# GD32F4xx register map
File version: 1.0
CPU: CM4 r2p1, little endian, MPU, FPU, 4 interrupt priority bits
Registers are 32-bit, read-write, reset 0x0 unless marked. A register's access mark holds for its fields unless they carry their own. Offsets are from the block's base; [hi:lo] are bit positions; {n}, {i} and the like mark numbered series; 'fields as' and 'values as' point back to an identical list.

## FWDGT — free watchdog timer
Base 0x40003000
0x00 CTL 16-bit wo — Control register
  [15:0] CMD — Key value
0x04 PSC — Prescaler register
  [2:0] PSC — Prescaler divider
0x08 RLD reset 0xFFF — Reload register
  [11:0] RLD — Free watchdog timer counter reload value
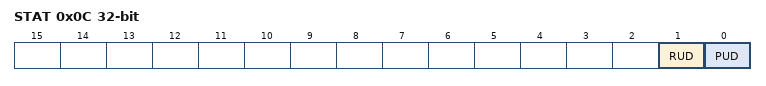
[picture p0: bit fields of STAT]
0x0C STAT ro — Status register
  [1] RUD — Free watchdog timer counter reload value update
  [0] PUD — Free watchdog timer prescaler value update

## GPIOA — General-purpose I/Os
Base 0x40020000
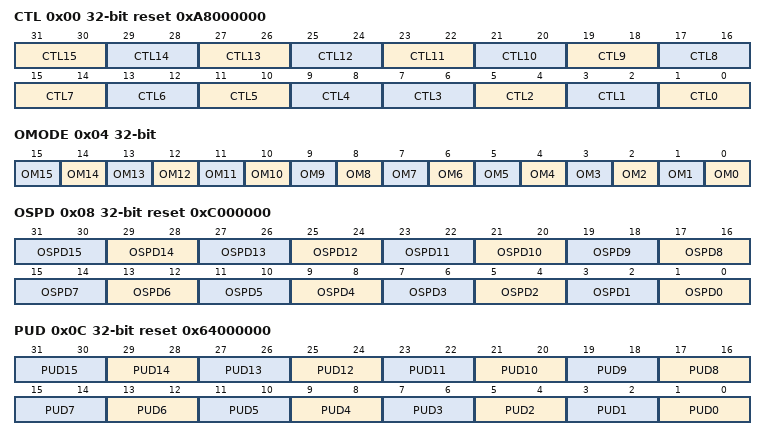
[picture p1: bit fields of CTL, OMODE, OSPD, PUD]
0x00 CTL reset 0xA8000000 — GPIO port control register
  [2n+1:2n] CTL{n} (n=7..15) — Port x configuration bits (x = {n})
  [13:12] CTL6 — Port x configuration bits (x = 6 )
  [11:10] CTL5 — Port x configuration bits (x = 5)
  [9:8] CTL4 — Port x configuration bits (x = 4 )
  [2n+1:2n] CTL{n} (n=0..3) — Port x configuration bits (x = {n})
0x04 OMODE — GPIO port output mode register
  [n] OM{n} (n=0..15) — Port {n} output mode bit
0x08 OSPD reset 0xC000000 — GPIO port output speed register
  [2n+1:2n] OSPD{n} (n=0..15) — Port {n} output max speed bits
0x0C PUD reset 0x64000000 — GPIO port pull-up/pull-down register
  [2n+1:2n] PUD{n} (n=0..15) — Port {n} pull-up or pull-down bits
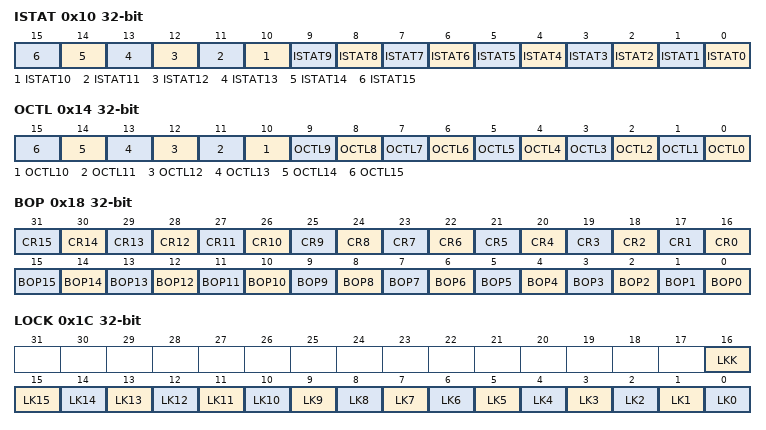
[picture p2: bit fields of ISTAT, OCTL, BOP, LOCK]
0x10 ISTAT ro — GPIO port input status register
  [n] ISTAT{n} (n=0..15) — Port input status (y = {n})
0x14 OCTL — GPIO port output control register
  [n] OCTL{n} (n=0..15) — Port output control (y = {n})
0x18 BOP wo — GPIO port bit operate register
  [n+16] CR{n} (n=0..15) — Port Clear bit {n}
  [n] BOP{n} (n=0..15) — Port Set bit {n}
0x1C LOCK — GPIO port configuration lock register
  [16] LKK — Lock sequence key
  [n] LK{n} (n=0..15) — Port Lock bit {n}
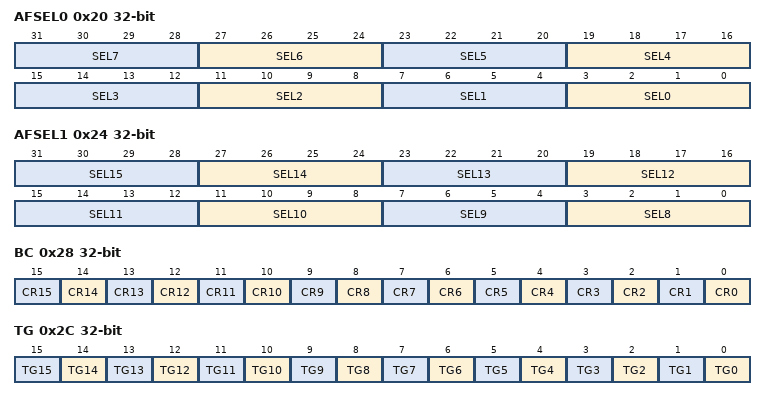
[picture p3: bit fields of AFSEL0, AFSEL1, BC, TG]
0x20 AFSEL0 — GPIO alternate function selected register 0
  [4n+3:4n] SEL{n} (n=0..7) — Port {n} alternate function selected
0x24 AFSEL1 — GPIO alternate function selected register 1
  [4n-29:4n-32] SEL{n} (n=8..15) — Port {n} alternate function selected
0x28 BC wo — Bit clear register
  [n] CR{n} (n=0..15) — Port cleat bit
0x2C TG wo — Port bit toggle register
  [n] TG{n} (n=0..15) — Port toggle bit

## GPIOB — General-purpose I/Os
Base 0x40020400
Registers as GPIOA; these are added or differ:
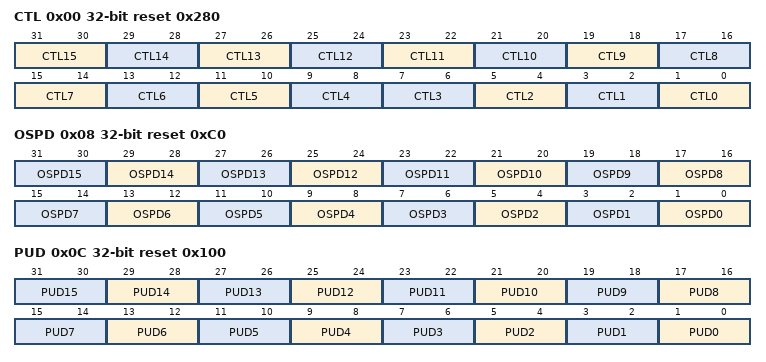
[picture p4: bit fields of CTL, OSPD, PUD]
0x00 CTL reset 0x280 — GPIO port control register
  fields as GPIOA.CTL
0x08 OSPD reset 0xC0 — GPIO port output speed register
  [2n+1:2n] OSPD{n} (n=0..15) — Port {n} output max speed bits
0x0C PUD reset 0x100 — GPIO port pull-up/pull-down register
  [2n+1:2n] PUD{n} (n=0..15) — Port {n} pull-up or pull-down bits

## GPIOC — General-purpose I/Os
Base 0x40020800
Same registers: GPIOD 0x40020C00, GPIOE 0x40021000, GPIOF 0x40021400, GPIOG 0x40021800, GPIOH 0x40021C00, GPIOI 0x40022000
Registers as GPIOA; these are added or differ:
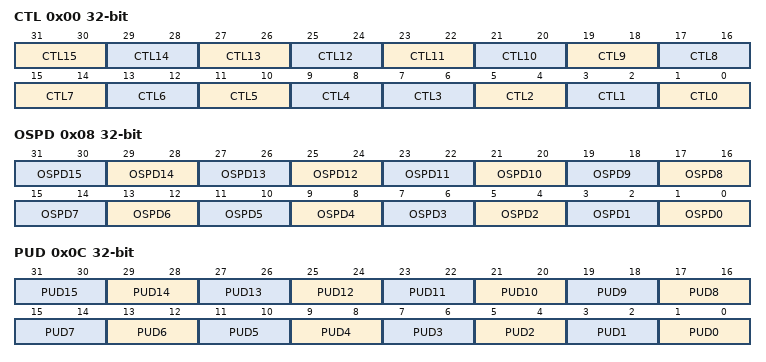
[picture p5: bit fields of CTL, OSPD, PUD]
0x00 CTL — GPIO port control register
  fields as GPIOA.CTL
0x08 OSPD — GPIO port output speed register
  [2n+1:2n] OSPD{n} (n=0..15) — Port {n} output max speed bits
0x0C PUD — GPIO port pull-up/pull-down register
  [2n+1:2n] PUD{n} (n=0..15) — Port {n} pull-up or pull-down bits

## IREF — Programmable current reference
Base 0x4000C400
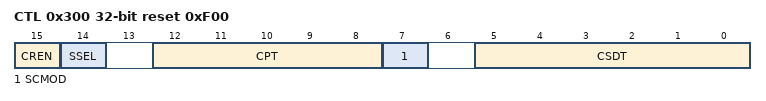
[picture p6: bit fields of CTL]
0x300 CTL reset 0xF00 — control register
  [15] CREN — Current reference enable
  [14] SSEL — Step selection
  [12:8] CPT — Current precision trim
  [7] SCMOD — Sink current mode
  [5:0] CSDT — Current step data

## NVIC — Nested Vectored Interrupt Controller
Base 0xE000E100
0x00 ISER — Interrupt Set Enable Register
  [31:0] SETENA
0x80 ICER — Interrupt Clear Enable Register
  [31:0] CLRENA
0x100 ISPR — Interrupt Set-Pending Register
  [31:0] SETPEND
0x180 ICPR — Interrupt Clear-Pending Register
  [31:0] CLRPEND
0x200 IABR — Interrupt Active bit Register
{0x300+i} IPR{i} 8-bit (i=0..73) — Interrupt Priority Register {i}
  [7:0] PRI_{i:02}
0xE00 STIR wo — Software Trigger Interrupt Register
